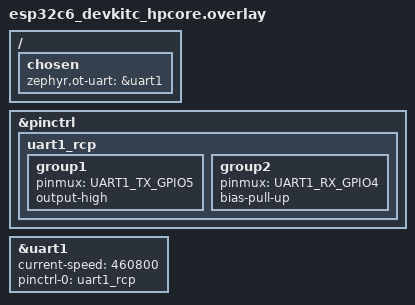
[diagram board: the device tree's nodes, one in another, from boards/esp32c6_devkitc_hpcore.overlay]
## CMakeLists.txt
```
cmake_minimum_required(VERSION 3.20.0)
find_package(Zephyr REQUIRED HINTS $ENV{ZEPHYR_BASE})
project(lab5_rcp)

target_sources(app PRIVATE src/main.c)
```

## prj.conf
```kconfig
# Based on $ZEPHYR_BASE/samples/net/openthread/coprocessor (prj.conf +
# overlay-rcp.conf).

CONFIG_NETWORKING=y
CONFIG_NET_L2_OPENTHREAD=y
CONFIG_OPENTHREAD_COPROCESSOR=y
CONFIG_OPENTHREAD_COPROCESSOR_RCP=y
# Must match the host. From 1.2 on, the RCP reports the software TX security
# and TX timing the host requires; the 1.1 default makes the host abort.
CONFIG_OPENTHREAD_THREAD_VERSION_1_4=y
# The 0 dBm default barely reaches past a few centimetres on these boards.
CONFIG_OPENTHREAD_DEFAULT_TX_POWER=20

CONFIG_NET_IPV6_NBR_CACHE=n
CONFIG_NET_IPV6_MLD=n
CONFIG_NET_PKT_RX_COUNT=8
CONFIG_NET_PKT_TX_COUNT=8

# Logs travel to the host inside Spinel frames
CONFIG_LOG=y
CONFIG_LOG_MAX_LEVEL=1
CONFIG_LOG_BACKEND_SPINEL=y
CONFIG_LOG_BACKEND_UART=n
CONFIG_LOG_PROCESS_THREAD_STACK_SIZE=2048
CONFIG_BOOT_BANNER=n

CONFIG_NVS=y
CONFIG_MAIN_STACK_SIZE=2560
CONFIG_INIT_STACKS=y
```

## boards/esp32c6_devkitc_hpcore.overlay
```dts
/* Spinel link to the ESP32-S3 host, crossed: C6 GPIO5 (TX) -> S3 GPIO4 (RX),
 * C6 GPIO4 (RX) <- S3 GPIO5 (TX), plus GND.
 */
/ {
	chosen {
		zephyr,ot-uart = &uart1;
	};
};

&pinctrl {
	uart1_rcp: uart1_rcp {
		group1 {
			pinmux = <UART1_TX_GPIO5>;
			output-high;
		};

		group2 {
			pinmux = <UART1_RX_GPIO4>;
			bias-pull-up;
		};
	};
};

&uart1 {
	status = "okay";
	current-speed = <460800>;
	pinctrl-0 = <&uart1_rcp>;
	pinctrl-names = "default";
};
```

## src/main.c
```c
/* OpenThread runs as a Radio Co-Processor: Spinel frames on uart1 drive the
 * 802.15.4 radio. There is no application code.
 */
int main(void)
{
	return 0;
}
```
